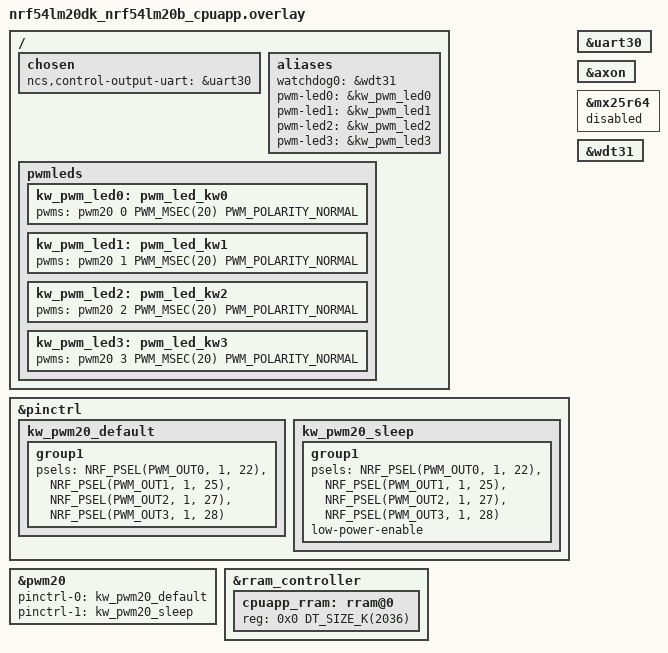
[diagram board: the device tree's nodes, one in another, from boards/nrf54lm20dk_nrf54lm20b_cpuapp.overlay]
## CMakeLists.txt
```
#
# Copyright (c) 2026 Nordic Semiconductor ASA
#
# SPDX-License-Identifier: LicenseRef-Nordic-5-Clause
#

cmake_minimum_required(VERSION 3.20.0)

find_package(Zephyr REQUIRED HINTS $ENV{ZEPHYR_BASE})
project(matter_ambient_sensing)

# Enable GNU STD support.
include(${ZEPHYR_CONNECTEDHOMEIP_MODULE_DIR}/config/nrfconnect/app/enable-gnu-std.cmake)

# NORDIC SDK APP START

# Include all source files that are located in the Matter common directory.
include(${ZEPHYR_NRF_MODULE_DIR}/samples/matter/common/cmake/source_common.cmake)

# Include Data Model utils
include(${ZEPHYR_NRF_MODULE_DIR}/samples/matter/common/cmake/data_model.cmake)

include(${ZEPHYR_NRF_MODULE_DIR}/samples/matter/common/cmake/zap_helpers.cmake)
ncs_get_zap_parent_dir(ZAP_PARENT_DIR)

set(MATTER_EDGEAI_COMMON_DIR ${CMAKE_CURRENT_SOURCE_DIR}/../matter_common)

target_include_directories(app PRIVATE
  src
  src/edgeAI
  ${MATTER_EDGEAI_COMMON_DIR}
  ${ZAP_PARENT_DIR}
)

target_compile_options(app PRIVATE -Wno-deprecated-declarations)

target_sources(app PRIVATE
  src/main.cpp
  src/app_task.cpp
  src/nrf_edgeai_task.cpp

  src/ambient_sensing.cpp

  ${MATTER_EDGEAI_COMMON_DIR}/dmic.c
  ${MATTER_EDGEAI_COMMON_DIR}/dimming_effect.cpp
)

target_sources_ifdef(CONFIG_AMBIENT_SENSING_MODEL_SNORING app PRIVATE src/models/snoring/nrf_edgeai_user_model.c)
target_sources_ifdef(CONFIG_AMBIENT_SENSING_MODEL_DOG_BARKING app PRIVATE src/models/dog_barking/nrf_edgeai_user_model.c)
target_sources_ifdef(CONFIG_AMBIENT_SENSING_MODEL_CAT_MEOWING app PRIVATE src/models/cat_meowing/nrf_edgeai_user_model.c)
target_sources_ifdef(CONFIG_AMBIENT_SENSING_MODEL_BABY_CRYING app PRIVATE src/models/baby_crying/nrf_edgeai_user_model.c)

ncs_configure_data_model()
```

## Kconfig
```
#
# Copyright (c) 2026 Nordic Semiconductor ASA
#
# SPDX-License-Identifier: LicenseRef-Nordic-5-Clause
#

rsource "../matter_common/Kconfig.edgeai"

menu "Matter Edge AI Switch"

choice AMBIENT_SENSING_MODEL
	prompt "Matter Ambient Sensing model"
	default AMBIENT_SENSING_MODEL_SNORING
	help
	  Choose the type of ambient sensing source to use.

config AMBIENT_SENSING_MODEL_SNORING
	bool "Snoring"
	help
	  Use the Snoring model for ambient sensing.

config AMBIENT_SENSING_MODEL_BABY_CRYING
	bool "Crying"
	help
	  Use the Baby Crying model for ambient sensing.

config AMBIENT_SENSING_MODEL_DOG_BARKING
	bool "Barking"
	help
	  Use the Barking model for ambient sensing.

config AMBIENT_SENSING_MODEL_CAT_MEOWING
	bool "Cat Meowing"
	help
	  Use the Meowing model for ambient sensing.

config AMBIENT_SENSING_MODEL_CUSTOM
	bool "Custom model"
	help
	  Use a custom model for ambient sensing.

endchoice

config AMBIENT_SENSING_MODEL_CUSTOM_PATH
	string "Path to the custom model"
	default ""
	help
	  Path to the custom model,

config AMBIENT_SENSING_ENDPOINT_ID
	int "Ambient Sensing Endpoint ID"
	default 1
	help
	  Endpoint ID for the ambient sensing.

config AI_THREAD_STACK_SIZE
	int "Edge AI thread stack size"
	default 6144
	help
	  Stack size for AI thread.

config AI_THREAD_PRIORITY
	int "Edge AI thread priority"
	default 8
	help
	  Preemptible thread priority.

endmenu

config USE_OCCUPANCY_SENSOR_INSTEAD_OF_AMBIENT_SENSING
	bool "Use occupancy sensor instead of ambient sensing"
	default y
	help
	  Use occupancy sensor instead of ambient sensing for testing purposes.

config NCS_SAMPLE_MATTER_ZAP_FILE_PATH
	default "${APPLICATION_CONFIG_DIR}/src/occupancy_sensor_zap/occupancy_sensor.zap" if USE_OCCUPANCY_SENSOR_INSTEAD_OF_AMBIENT_SENSING
	default "${APPLICATION_CONFIG_DIR}/src/ambient_sensing_zap/ambient_sensing.zap"

# Sample configuration used for Thread networking
if OPENTHREAD

choice OPENTHREAD_NORDIC_LIBRARY_CONFIGURATION
	default OPENTHREAD_NORDIC_LIBRARY_FTD
endchoice

choice OPENTHREAD_DEVICE_TYPE
	default OPENTHREAD_FTD
endchoice

endif # OPENTHREAD

source "$(ZEPHYR_CONNECTEDHOMEIP_MODULE_DIR)/config/nrfconnect/chip-module/Kconfig.features"
source "$(ZEPHYR_CONNECTEDHOMEIP_MODULE_DIR)/config/nrfconnect/chip-module/Kconfig.defaults"
source "$(ZEPHYR_NRF_MODULE_DIR)/samples/matter/common/src/Kconfig"
source "Kconfig.zephyr"
```

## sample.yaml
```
sample:
  description: Matter Switch application
  name: Matter Switch

common:
  sysbuild: true
  build_only: true
  tags:
    - ci_build
    - sysbuild

tests:
  applications.matter_ambient_sensing.snoring_dmic_adafruit:
    extra_args:
      - CONFIG_AMBIENT_SENSING_MODEL_SNORING=y
      - EXTRA_DTC_OVERLAY_FILE=boards/dmic_adafruit.dtsi
    platform_allow:
      - nrf54lm20dk/nrf54lm20b/cpuapp
    integration_platforms:
      - nrf54lm20dk/nrf54lm20b/cpuapp
  applications.matter_ambient_sensing.snoring_dmic_low_power:
    extra_args:
      - CONFIG_AMBIENT_SENSING_MODEL_SNORING=y
      - EXTRA_DTC_OVERLAY_FILE=boards/dmic_low_power.dtsi
    platform_allow:
      - nrf54lm20dk/nrf54lm20b/cpuapp
    integration_platforms:
      - nrf54lm20dk/nrf54lm20b/cpuapp
  applications.matter_ambient_sensing.baby_crying_dmic_adafruit:
    extra_args:
      - CONFIG_AMBIENT_SENSING_MODEL_BABY_CRYING=y
      - EXTRA_DTC_OVERLAY_FILE=boards/dmic_adafruit.dtsi
    platform_allow:
      - nrf54lm20dk/nrf54lm20b/cpuapp
    integration_platforms:
      - nrf54lm20dk/nrf54lm20b/cpuapp
  applications.matter_ambient_sensing.baby_crying_dmic_low_power:
    extra_args:
      - CONFIG_AMBIENT_SENSING_MODEL_BABY_CRYING=y
      - EXTRA_DTC_OVERLAY_FILE=boards/dmic_low_power.dtsi
    platform_allow:
      - nrf54lm20dk/nrf54lm20b/cpuapp
    integration_platforms:
      - nrf54lm20dk/nrf54lm20b/cpuapp
  applications.matter_ambient_sensing.dog_barking_dmic_adafruit:
    extra_args:
      - CONFIG_AMBIENT_SENSING_MODEL_DOG_BARKING=y
      - EXTRA_DTC_OVERLAY_FILE=boards/dmic_adafruit.dtsi
    platform_allow:
      - nrf54lm20dk/nrf54lm20b/cpuapp
    integration_platforms:
      - nrf54lm20dk/nrf54lm20b/cpuapp
  applications.matter_ambient_sensing.dog_barking_dmic_low_power:
    extra_args:
      - CONFIG_AMBIENT_SENSING_MODEL_DOG_BARKING=y
      - EXTRA_DTC_OVERLAY_FILE=boards/dmic_low_power.dtsi
    platform_allow:
      - nrf54lm20dk/nrf54lm20b/cpuapp
    integration_platforms:
      - nrf54lm20dk/nrf54lm20b/cpuapp
  applications.matter_ambient_sensing.cat_meowing_dmic_adafruit:
    extra_args:
      - CONFIG_AMBIENT_SENSING_MODEL_CAT_MEOWING=y
      - EXTRA_DTC_OVERLAY_FILE=boards/dmic_adafruit.dtsi
    platform_allow:
      - nrf54lm20dk/nrf54lm20b/cpuapp
    integration_platforms:
      - nrf54lm20dk/nrf54lm20b/cpuapp
  applications.matter_ambient_sensing.cat_meowing_dmic_low_power:
    extra_args:
      - CONFIG_AMBIENT_SENSING_MODEL_CAT_MEOWING=y
      - EXTRA_DTC_OVERLAY_FILE=boards/dmic_low_power.dtsi
    platform_allow:
      - nrf54lm20dk/nrf54lm20b/cpuapp
    integration_platforms:
      - nrf54lm20dk/nrf54lm20b/cpuapp
```

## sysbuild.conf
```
#
# Copyright (c) 2026 Nordic Semiconductor ASA
#
# SPDX-License-Identifier: LicenseRef-Nordic-5-Clause
#

SB_CONFIG_MATTER=y
SB_CONFIG_MATTER_FACTORY_DATA_GENERATE=y

SB_CONFIG_PARTITION_MANAGER=y
SB_CONFIG_PM_OVERRIDE_EXTERNAL_DRIVER_CHECK=n
SB_CONFIG_PM_EXTERNAL_FLASH_MCUBOOT_SECONDARY=n

# Enable the DFU image compression.
SB_CONFIG_BOOTLOADER_MCUBOOT=y
SB_CONFIG_DFU_MULTI_IMAGE_PACKAGE_BUILD=y
SB_CONFIG_DFU_MULTI_IMAGE_PACKAGE_APP=y
SB_CONFIG_MCUBOOT_MODE_OVERWRITE_ONLY=y
SB_CONFIG_MCUBOOT_COMPRESSED_IMAGE_SUPPORT=y
```

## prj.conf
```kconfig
#
# Copyright (c) 2026 Nordic Semiconductor
#
# SPDX-License-Identifier: LicenseRef-Nordic-5-Clause
#

# Enable CHIP
CONFIG_CHIP=y
CONFIG_CHIP_PROJECT_CONFIG="src/chip_project_config.h"
CONFIG_CHIP_DEVICE_PRODUCT_NAME="Matter Ambient Sensing"

# 32768 == 0x8000 (example Product ID added temporaly,
# but it must be changed with proper PID from the list:
# https://github.com/project-chip/connectedhomeip/blob/482e6fd03196a6de45465a90003947ef4b86e0b1/docs/examples/discussion/PID_allocation_for_example_apps.md)
CONFIG_CHIP_DEVICE_PRODUCT_ID=32768
CONFIG_STD_CPP17=y

# Enable Matter extended announcement and increase duration to 1 hour.
CONFIG_CHIP_BLE_EXT_ADVERTISING=y
CONFIG_CHIP_BLE_ADVERTISING_DURATION=60

# Add support for LEDs and buttons on Nordic development kits
CONFIG_DK_LIBRARY=y

# Bluetooth Low Energy configuration
CONFIG_BT_DEVICE_NAME="MatterAmbient"

# Enable Matter pairing automatically on application start.
CONFIG_CHIP_ENABLE_PAIRING_AUTOSTART=y

# Suspend devices when the CPU goes into sleep
CONFIG_PM_DEVICE=y

# Other settings
CONFIG_THREAD_NAME=y
CONFIG_MPU_STACK_GUARD=y

# Memory: k_malloc pool + Matter chip heap are static (.bss) and sit before the Newlib arena
# (RAM from _end to top of SRAM). Edge AI uses malloc(); if that arena is too small, the first
# stdio/C++ lock init hits: "recursive lock allocation failed" in libc-hooks.c.
CONFIG_MAIN_STACK_SIZE=10240
CONFIG_COMMON_LIBC_MALLOC_ARENA_SIZE=-1
CONFIG_NEWLIB_LIBC_MIN_REQUIRED_HEAP_SIZE=40960
CONFIG_HEAP_MEM_POOL_SIZE=24576
CONFIG_CHIP_MALLOC_SYS_HEAP_SIZE=40960
CONFIG_CHIP_SYSTEM_PACKETBUFFER_POOL_SIZE=24
CONFIG_CHIP_TASK_STACK_SIZE=12288
CONFIG_AI_THREAD_STACK_SIZE=8192
CONFIG_AI_THREAD_PRIORITY=0

CONFIG_RESET_ON_FATAL_ERROR=n
CONFIG_CHIP_LIB_SHELL=y
CONFIG_NCS_SAMPLE_MATTER_TEST_SHELL=y

# Reduce application size
CONFIG_USE_SEGGER_RTT=n
CONFIG_MATTER_LOG_LEVEL_INF=y
CONFIG_CHIP_APP_LOG_LEVEL=3

# Enable Factory Data feature
CONFIG_CHIP_FACTORY_DATA=y
CONFIG_CHIP_FACTORY_DATA_BUILD=y

# nRF Edge AI
CONFIG_NRF_EDGEAI=y

# nRF Edge AI dependencies
CONFIG_NRF_AXON=y
CONFIG_NEWLIB_LIBC=y
CONFIG_FPU=y

# Size of interlayer buffer to fit model
CONFIG_NRF_AXON_INTERLAYER_BUFFER_SIZE=6048

# Size of psum buffer to fit model
CONFIG_NRF_AXON_PSUM_BUFFER_SIZE=0

# Enable sensor, button and LED libraries
CONFIG_GPIO=y
CONFIG_AUDIO=y
CONFIG_AUDIO_DMIC=y

# PWM-driven LED dimming on wakeword
CONFIG_PWM=y
```

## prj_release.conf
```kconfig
#
# Copyright (c) 2021 Nordic Semiconductor ASA
#
# SPDX-License-Identifier: LicenseRef-Nordic-5-Clause
#

# This sample uses Kconfig.defaults to set options common for all
# samples. This file should contain only options specific for this sample
# or overrides of default values.

# Enable CHIP
CONFIG_CHIP=y
CONFIG_CHIP_PROJECT_CONFIG="src/chip_project_config.h"
CONFIG_CHIP_DEVICE_PRODUCT_NAME="Matter Switch"

# Configure ZAP file name
CONFIG_NCS_SAMPLE_MATTER_ZAP_FILE_PATH="${APPLICATION_CONFIG_DIR}/src/default_zap/ai_switch.zap"

# 32772 == 0x8004 (example ai_switch-app)
CONFIG_CHIP_DEVICE_PRODUCT_ID=32772
CONFIG_STD_CPP17=y

# Enable Matter extended announcement and increase duration to 1 hour.
CONFIG_CHIP_BLE_EXT_ADVERTISING=y
CONFIG_CHIP_BLE_ADVERTISING_DURATION=60

# Enable Matter pairing automatically on application start.
CONFIG_CHIP_ENABLE_PAIRING_AUTOSTART=y

# Enable Matter extended announcement and increase duration to 1 hour.
CONFIG_CHIP_BLE_EXT_ADVERTISING=y
CONFIG_CHIP_BLE_ADVERTISING_DURATION=60

# Add support for LEDs and buttons on Nordic development kits
CONFIG_DK_LIBRARY=y

# Bluetooth Low Energy configuration
CONFIG_BT_DEVICE_NAME="MatterSwitch"

# Enable system reset on fatal error
CONFIG_RESET_ON_FATAL_ERROR=y

# Disable all debug features
CONFIG_USE_SEGGER_RTT=n
CONFIG_SHELL=n
CONFIG_OPENTHREAD_SHELL=n
CONFIG_CHIP_LIB_SHELL=n
CONFIG_CONSOLE=n
CONFIG_UART_CONSOLE=n
CONFIG_SERIAL=n
CONFIG_LOG=n
CONFIG_LOG_MODE_MINIMAL=n
CONFIG_ASSERT_VERBOSE=n
CONFIG_ASSERT_NO_FILE_INFO=y
CONFIG_PRINTK=n
CONFIG_PRINTK_SYNC=n
CONFIG_THREAD_NAME=n
CONFIG_BOOT_BANNER=n

# Disable NFC onboarding
CONFIG_CHIP_NFC_ONBOARDING_PAYLOAD=n

# Enable Factory Data feature
CONFIG_CHIP_FACTORY_DATA=y
CONFIG_CHIP_FACTORY_DATA_BUILD=y

# Enable Watchdog
CONFIG_NCS_SAMPLE_MATTER_WATCHDOG=y

# Enable LTO to decrease the flash usage.
CONFIG_LTO=y
CONFIG_ISR_TABLES_LOCAL_DECLARATION=y


# nRF Edge AI
CONFIG_NRF_EDGEAI=y

# nRF Edge AI dependencies
CONFIG_NRF_AXON=y
CONFIG_NEWLIB_LIBC=y
CONFIG_FPU=y

# Size of interlayer buffer to fit model
CONFIG_NRF_AXON_INTERLAYER_BUFFER_SIZE=6048

# Size of psum buffer to fit model
CONFIG_NRF_AXON_PSUM_BUFFER_SIZE=0

# Enable sensor, button and LED libraries
CONFIG_GPIO=y
CONFIG_AUDIO=y
CONFIG_AUDIO_DMIC=y
```

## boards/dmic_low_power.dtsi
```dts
/*
 * Copyright (c) 2026 Nordic Semiconductor ASA
 *
 * SPDX-License-Identifier: LicenseRef-Nordic-5-Clause
 */

&pinctrl {
	pdm20_default_alt: pdm20_default_alt {
		group1 {
			psels = <NRF_PSEL(PDM_CLK, 1, 12)>,
				<NRF_PSEL(PDM_DIN, 1, 8)>;
		};
	};
};

dmic_dev: &pdm20 {
	status = "okay";
	pinctrl-0 = <&pdm20_default_alt>;
	pinctrl-names = "default";
	clock-source = "PCLK32M";
	queue-size = <12>;
};
```

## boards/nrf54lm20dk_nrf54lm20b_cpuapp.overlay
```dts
/*
 * Copyright (c) 2026 Nordic Semiconductor ASA
 *
 * SPDX-License-Identifier: LicenseRef-Nordic-5-Clause
 */

/ {
	chosen {
		ncs,control-output-uart = &uart30;
	};

	aliases {
		/* Use watchdog wdt31 as the application watchdog */
		watchdog0 = &wdt31;

		/delete-property/ pwm-led0;
		pwm-led0 = &kw_pwm_led0;
		pwm-led1 = &kw_pwm_led1;
		pwm-led2 = &kw_pwm_led2;
		pwm-led3 = &kw_pwm_led3;
	};

	pwmleds {
		kw_pwm_led0: pwm_led_kw0 {
			pwms = <&pwm20 0 PWM_MSEC(20) PWM_POLARITY_NORMAL>;
		};

		kw_pwm_led1: pwm_led_kw1 {
			pwms = <&pwm20 1 PWM_MSEC(20) PWM_POLARITY_NORMAL>;
		};

		kw_pwm_led2: pwm_led_kw2 {
			pwms = <&pwm20 2 PWM_MSEC(20) PWM_POLARITY_NORMAL>;
		};

		kw_pwm_led3: pwm_led_kw3 {
			pwms = <&pwm20 3 PWM_MSEC(20) PWM_POLARITY_NORMAL>;
		};
	};
};

&pinctrl {
	kw_pwm20_default: kw_pwm20_default {
		group1 {
			psels = <NRF_PSEL(PWM_OUT0, 1, 22)>,
				<NRF_PSEL(PWM_OUT1, 1, 25)>,
				<NRF_PSEL(PWM_OUT2, 1, 27)>,
				<NRF_PSEL(PWM_OUT3, 1, 28)>;
		};
	};

	kw_pwm20_sleep: kw_pwm20_sleep {
		group1 {
			psels = <NRF_PSEL(PWM_OUT0, 1, 22)>,
				<NRF_PSEL(PWM_OUT1, 1, 25)>,
				<NRF_PSEL(PWM_OUT2, 1, 27)>,
				<NRF_PSEL(PWM_OUT3, 1, 28)>;
			low-power-enable;
		};
	};
};

&pwm20 {
	pinctrl-0 = <&kw_pwm20_default>;
	pinctrl-1 = <&kw_pwm20_sleep>;
	pinctrl-names = "default", "sleep";
};

&rram_controller {
	cpuapp_rram: rram@0 {
		reg = <0x0 DT_SIZE_K(2036)>;
		ranges = <0x0 0x0 DT_SIZE_K(2036)>;
	};
};

&uart30 {
	status = "okay";
};

&axon {
	status = "okay";
};

&mx25r64 {
	status = "disabled";
};

&wdt31 {
	status = "okay";
};
```

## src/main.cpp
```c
/*
 * Copyright (c) 2026 Nordic Semiconductor ASA
 *
 * SPDX-License-Identifier: LicenseRef-Nordic-5-Clause
 */

#include "app_task.h"

#include <zephyr/logging/log.h>

LOG_MODULE_REGISTER(app, CONFIG_CHIP_APP_LOG_LEVEL);

int main()
{
	CHIP_ERROR err = AppTask::Instance().StartApp();

	LOG_ERR("Exited with code %" CHIP_ERROR_FORMAT, err.Format());
	return err == CHIP_NO_ERROR ? EXIT_SUCCESS : EXIT_FAILURE;
}
```

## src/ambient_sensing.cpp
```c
/*
 * Copyright (c) 2026 Nordic Semiconductor ASA
 *
 * SPDX-License-Identifier: LicenseRef-Nordic-5-Clause
 */

#include "ambient_sensing.h"

#include <zephyr/kernel.h>
#include <zephyr/logging/log.h>
#include <zephyr/sys/__assert.h>
#include <nrf_edgeai/nrf_edgeai.h>

#include "models/all_models.h"

LOG_MODULE_REGISTER(ambient_sensing, LOG_LEVEL_INF);

#if defined(CONFIG_AMBIENT_SENSING_MODEL_SNORING)
#define CONFIDENCE_THRESHOLD	  0.9f
#define PREDICTION_NUM_IN_ROW	  20
#define MAX_PREDICTION_NUM_IN_ROW 31
#define PRINT_RAW_PROBABILITY	  0
const char *MODEL_NAME = "Snoring";
#elif defined(CONFIG_AMBIENT_SENSING_MODEL_BABY_CRYING)
#define CONFIDENCE_THRESHOLD	  0.996078f
#define PREDICTION_NUM_IN_ROW	  3
#define MAX_PREDICTION_NUM_IN_ROW 31
#define PRINT_RAW_PROBABILITY	  0
const char *MODEL_NAME = "Baby Crying";
#elif defined(CONFIG_AMBIENT_SENSING_MODEL_DOG_BARKING)
#define CONFIDENCE_THRESHOLD	  0.9f
#define PREDICTION_NUM_IN_ROW	  10
#define MAX_PREDICTION_NUM_IN_ROW 31
#define PRINT_RAW_PROBABILITY	  0
const char *MODEL_NAME = "Dog Barking";
#elif defined(CONFIG_AMBIENT_SENSING_MODEL_CAT_MEOWING)
#define CONFIDENCE_THRESHOLD	  0.95f
#define PREDICTION_NUM_IN_ROW	  9
#define MAX_PREDICTION_NUM_IN_ROW 31
#define PRINT_RAW_PROBABILITY	  0
const char *MODEL_NAME = "Cat Meowing";
#endif

namespace Nrf
{
namespace AmbientSensing
{

const char *getModelName()
{
	return MODEL_NAME;
}

bool process(nrf_edgeai_t *p_model)
{
	// Rolling postprocessing state kept across calls.
	// - predictions_history stores recent boolean detections as bits (newest at bit 0).
	// - prediction_count tracks how many `1` bits are currently in the window.
	static uint32_t prediction_count;
	static uint32_t predictions_history;

	// Read model confidence for the currently predicted class.
	const uint16_t predicted_class = p_model->decoded_output.classif.predicted_class;
	const float probability =
		p_model->decoded_output.classif.probabilities.p_f32[predicted_class];

	// Convert probability to a binary detection for this frame.
	const bool detected = probability > CONFIDENCE_THRESHOLD;

	// Check the bit that will fall out of the window after the left shift.
	// MAX_PREDICTION_NUM_IN_ROW is the history bit-width limit used by this algorithm.
	const bool oldest_entry = (bool)(predictions_history & BIT(MAX_PREDICTION_NUM_IN_ROW));

	// Update rolling count in O(1): add newest detection, remove oldest.
	prediction_count = prediction_count + detected - oldest_entry;
	// Shift history left and append current detection at LSB.
	predictions_history = (predictions_history << 1) | detected;

#if PRINT_RAW_PROBABILITY
	LOG_DBG("Predictions count: %2u, probability: %0.3f", prediction_count,
		static_cast<double>(probability));
#endif

	if (prediction_count >= PREDICTION_NUM_IN_ROW) {
		// Enough positive frames accumulated: emit one detection event
		// and clear state to avoid repeated triggers from stale history.
		prediction_count = 0;
		predictions_history = 0;

		return true;
	}

	return false;
}
} // namespace AmbientSensing
} // namespace Nrf
```

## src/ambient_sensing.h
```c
/*
 * Copyright (c) 2026 Nordic Semiconductor ASA
 *
 * SPDX-License-Identifier: LicenseRef-Nordic-5-Clause
 */

#pragma once

#include <nrf_edgeai/nrf_edgeai.h>

namespace Nrf
{
namespace AmbientSensing
{
    bool process(nrf_edgeai_t *p_model);
    const char* getModelName();

} // namespace AmbientSensing
} // namespace Nrf
```

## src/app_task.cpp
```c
/*
 * Copyright (c) 2021 Nordic Semiconductor ASA
 *
 * SPDX-License-Identifier: LicenseRef-Nordic-5-Clause
 */

#include "app_task.h"

#include "app/matter_init.h"
#include "app/task_executor.h"
#include "board/board.h"
#include "clusters/identify.h"
#include "lib/core/CHIPError.h"
#include "nrf_edgeai_task.h"

#include <zephyr/logging/log.h>

LOG_MODULE_DECLARE(app, CONFIG_CHIP_APP_LOG_LEVEL);

using namespace ::chip;
using namespace ::chip::app;
using namespace ::chip::app::Clusters;
using namespace ::chip::app::Clusters::OnOff;
using namespace ::chip::DeviceLayer;

namespace
{
Nrf::Matter::IdentifyCluster sIdentifyCluster(CONFIG_AMBIENT_SENSING_ENDPOINT_ID);

void matter_app_event_handler(const chip::DeviceLayer::ChipDeviceEvent *event, intptr_t arg)
{
	(void)arg;

	switch (event->Type) {
	case chip::DeviceLayer::DeviceEventType::kServerReady:
		// Enable Edge AI task when Matter server is ready
		EdgeAITask::Instance().Enable();
		break;
	case chip::DeviceLayer::DeviceEventType::kCHIPoBLEConnectionEstablished:
		// Disable Edge AI task when commissioning is in progress
		EdgeAITask::Instance().Disable();
		break;
	default:
		break;
	}
}
} // namespace

CHIP_ERROR AppTask::Init()
{
	ReturnErrorOnFailure(Nrf::Matter::PrepareServer(
		Nrf::Matter::InitData{.mPostServerInitClbk = [] { return CHIP_NO_ERROR; }}));

	if (!Nrf::GetBoard().Init()) {
		LOG_ERR("User interface initialization failed.");
		return CHIP_ERROR_INCORRECT_STATE;
	}

	ReturnErrorOnFailure(Nrf::Matter::RegisterEventHandler(matter_app_event_handler, 0));
	ReturnErrorOnFailure(
		Nrf::Matter::RegisterEventHandler(Nrf::Board::DefaultMatterEventHandler, 0));

	ReturnErrorOnFailure(sIdentifyCluster.Init());

	return Nrf::Matter::StartServer();
}

CHIP_ERROR AppTask::StartApp()
{
	ReturnErrorOnFailure(Init());

	ReturnErrorOnFailure(EdgeAITask::Instance().Start());
	EdgeAITask::Instance().Enable();

	while (true) {
		Nrf::DispatchNextTask();
	}

	return CHIP_NO_ERROR;
}
```

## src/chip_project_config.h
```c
/*
 * Copyright (c) 2021 Nordic Semiconductor ASA
 *
 * SPDX-License-Identifier: LicenseRef-Nordic-5-Clause
 */

/**
 *    @file
 *          Example project configuration file for CHIP.
 *
 *          This is a place to put application or project-specific overrides
 *          to the default configuration values for general CHIP features.
 *
 */

#pragma once

/* Empty file */
```

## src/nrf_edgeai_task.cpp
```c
/*
 * Copyright (c) 2026 Nordic Semiconductor ASA
 *
 * SPDX-License-Identifier: LicenseRef-Nordic-5-Clause
 */

#include <errno.h>

#include <zephyr/audio/dmic.h>
#include <zephyr/device.h>
#include <zephyr/devicetree.h>
#include <zephyr/kernel.h>

#include "board/board.h"
#include "app/task_executor.h"
#include "dimming_effect.h"

#include "dmic.h"
#include "nrf_edgeai_task.h"
#include "app_task.h"
#include "ambient_sensing.h"
#include "models/all_models.h"

#include <app-common/zap-generated/attributes/Accessors.h>
#include <app-common/zap-generated/cluster-objects.h>
#include <app-common/zap-generated/ids/Clusters.h>
#include <app/EventLogging.h>
#include <platform/CHIPDeviceLayer.h>

#include <zephyr/logging/log.h>

LOG_MODULE_DECLARE(app, CONFIG_CHIP_APP_LOG_LEVEL);

using namespace ::chip;
using namespace ::chip::app;
using namespace ::chip::app::Clusters;
using namespace ::chip::DeviceLayer;

namespace
{
const struct device *const dmic_dev = DEVICE_DT_GET(DT_NODELABEL(dmic_dev));

#ifdef CONFIG_USE_OCCUPANCY_SENSOR_INSTEAD_OF_AMBIENT_SENSING
void ApplyOccupancyValue(EndpointId endpointId, uint8_t newOccupancyValue)
{
	using chip::BitMask;
	using chip::Protocols::InteractionModel::Status;

	BitMask<Clusters::OccupancySensing::OccupancyBitmap> currentOccupancy;
	Status status = Clusters::OccupancySensing::Attributes::Occupancy::Get(endpointId,
									       &currentOccupancy);

	if (status != Status::Success) {
		LOG_ERR("Occupancy::Get failed: %u", static_cast<unsigned>(to_underlying(status)));
		return;
	}

	if (static_cast<BitMask<Clusters::OccupancySensing::OccupancyBitmap>>(newOccupancyValue) ==
	    currentOccupancy) {
		return;
	}

	status = Clusters::OccupancySensing::Attributes::Occupancy::Set(endpointId,
									newOccupancyValue);
	if (status != Status::Success) {
		LOG_ERR("Occupancy::Set failed: %u", static_cast<unsigned>(to_underlying(status)));
		return;
	}

	if (newOccupancyValue == 1) {
		LOG_INF("Occupancy is now occupied");
	} else {
		LOG_INF("Occupancy is now vacant");
	}
}

void OccupancySensingChipWorkerHandler(intptr_t arg)
{
	ApplyOccupancyValue(CONFIG_AMBIENT_SENSING_ENDPOINT_ID, static_cast<uint8_t>(arg));
}

CHIP_ERROR RequestOccupancyMatterUpdate(uint8_t occupancyRaw)
{
	return DeviceLayer::PlatformMgr().ScheduleWork(OccupancySensingChipWorkerHandler,
						       static_cast<intptr_t>(occupancyRaw));
}
#endif

void ai_thread_fn()
{
	void *audio_buffer;
	size_t audio_buffer_size;
	const int32_t read_timeout = 100;
	int err = 0;

	LOG_INF("Starting Ambient Sensing Application...");
	LOG_INF("Model postprocessing adjustable parameters:");

	nrf_edgeai_rt_version_t libver = nrf_edgeai_runtime_version();
	LOG_INF("Nordic Edge AI Library version: %d.%d.%d", libver.field.major, libver.field.minor,
		libver.field.patch);

	nrf_edgeai_t *p_model = get_ambient_sensing_model();

	// Initialize ambient sensing model
	nrf_edgeai_err_t res = nrf_edgeai_init(p_model);
	if (res != NRF_EDGEAI_ERR_SUCCESS) {
		LOG_ERR("Failed to initialize Edge AI model %s, error code: %d",
			Nrf::AmbientSensing::getModelName(), res);
		return;
	}

	if (dmic_init()) {
		LOG_ERR("Failed to initialize DMIC");
		return;
	}

#if defined(CONFIG_PWM) && DT_HAS_ALIAS(pwm_led0) && DT_HAS_ALIAS(pwm_led1) &&                     \
	DT_HAS_ALIAS(pwm_led2) && DT_HAS_ALIAS(pwm_led3)
	{
		Nrf::DimmingEffect::Config dim_cfg;

		dim_cfg.effect_timeout_s = 5;
		dim_cfg.blink_pairs_multiplier = 3;
		(void)Nrf::DimmingEffect::Init(
			dim_cfg,
			[](void *) {
#ifdef CONFIG_USE_OCCUPANCY_SENSOR_INSTEAD_OF_AMBIENT_SENSING
				if (RequestOccupancyMatterUpdate(0) != CHIP_NO_ERROR) {
					LOG_ERR("Failed to schedule occupancy clear to Matter "
						"stack");
				}
#endif
			},
			nullptr);
	}
#endif

	LOG_INF("Edge AI initialization completed");

	if (dmic_trigger(dmic_dev, DMIC_TRIGGER_START) < 0) {
		LOG_ERR("Failed to start DMIC");
		return;
	}

	while (true) {
		err = dmic_read(dmic_dev, 0, &audio_buffer, &audio_buffer_size, read_timeout);
		if (err != 0) {
			/* No data yet or driver busy: avoid a tight loop and log spam. */
			if (err == -EAGAIN || err == -EBUSY) {
				k_yield();
				continue;
			}
			LOG_WRN("DMIC read failed (err %d)", err);
			k_sleep(K_MSEC(1));
			continue;
		}

		if (!EdgeAITask::Instance().IsEnabled()) {
			free_dmic_buffer(audio_buffer);
			continue;
		}

		size_t samples_num = audio_buffer_size / DMIC_SAMPLE_BYTES;

		// Feed audio data to the model dsp pipeline and
		// waiting for internal buffers to be filled with enough data for feature extraction
		res = nrf_edgeai_feed_inputs(p_model, audio_buffer, samples_num);
		free_dmic_buffer(audio_buffer);

		if (res != NRF_EDGEAI_ERR_SUCCESS) {
			continue;
		}

		// Run feature extraction and model inference
		res = nrf_edgeai_run_inference(p_model);

		if (res != NRF_EDGEAI_ERR_SUCCESS) {
			continue;
		}

		// Run postprocessing on the model output to determine if snoring is detected based
		// on the model inference results
		if (Nrf::AmbientSensing::process(p_model)) {
			LOG_INF("%s detected", Nrf::AmbientSensing::getModelName());
			Nrf::PostTask([] {
#if defined(CONFIG_PWM) && DT_HAS_ALIAS(pwm_led0) && DT_HAS_ALIAS(pwm_led1) &&                     \
	DT_HAS_ALIAS(pwm_led2) && DT_HAS_ALIAS(pwm_led3)
				Nrf::DimmingEffect::Start();
#endif
			});
#ifdef CONFIG_USE_OCCUPANCY_SENSOR_INSTEAD_OF_AMBIENT_SENSING
			if (RequestOccupancyMatterUpdate(1) != CHIP_NO_ERROR) {
				LOG_ERR("Failed to schedule occupancy update to Matter stack");
			}
#endif
		}
	}
}

K_THREAD_DEFINE(ai_thread_id, CONFIG_AI_THREAD_STACK_SIZE, ai_thread_fn, NULL, NULL, NULL,
		CONFIG_AI_THREAD_PRIORITY, K_FP_REGS, SYS_FOREVER_MS);
} // namespace

CHIP_ERROR EdgeAITask::Start()
{
	k_thread_start(ai_thread_id);
	return CHIP_NO_ERROR;
}

void EdgeAITask::Enable()
{
	LOG_INF("\n\nWaiting for %s source...\n\n", Nrf::AmbientSensing::getModelName());
	enabled.store(true, std::memory_order_release);
}

void EdgeAITask::Disable()
{
	enabled.store(false, std::memory_order_release);
	LOG_INF("\n\nEdge AI listening disabled\n\n");
}

void MatterPostAttributeChangeCallback(const chip::app::ConcreteAttributePath &attributePath,
				       uint8_t type, uint16_t size, uint8_t *value)
{
	ClusterId clusterId = attributePath.mClusterId;
	AttributeId attributeId = attributePath.mAttributeId;

	if (clusterId == OccupancySensing::Id &&
	    attributeId == OccupancySensing::Attributes::Occupancy::Id) {
	}
}
```

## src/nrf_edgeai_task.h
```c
/*
 * Copyright (c) 2026 Nordic Semiconductor ASA
 *
 * SPDX-License-Identifier: LicenseRef-Nordic-5-Clause
 */

#pragma once

#include <platform/CHIPDeviceLayer.h>
#include <atomic>

class EdgeAITask
{
public:
	/**
	 * @brief Get the singleton instance of EdgeAITask.
	 * 
	 * @return Reference to the EdgeAITask instance.
	 */
	static EdgeAITask &Instance()
	{
		static EdgeAITask sEdgeAITask;
		return sEdgeAITask;
	};

	/**
	 * @brief Start the Edge AI task thread.
	 * 
	 * @return CHIP_ERROR indicating success or failure.
	 */
	CHIP_ERROR Start();

	/**
	 * @brief Enable the Edge AI task.
	 */
	void Enable();

	/**
	 * @brief Disable the Edge AI task.
	 */
	void Disable();

	/**
	 * @brief Check if the Edge AI task is enabled.
	 * 
	 * @return true if enabled, false otherwise.
	 */
	bool IsEnabled() const
	{
		return enabled.load(std::memory_order_acquire);
	}

private:
	/** @brief Flag indicating whether the Edge AI task is enabled. */
	std::atomic<bool> enabled{false};
};
```
